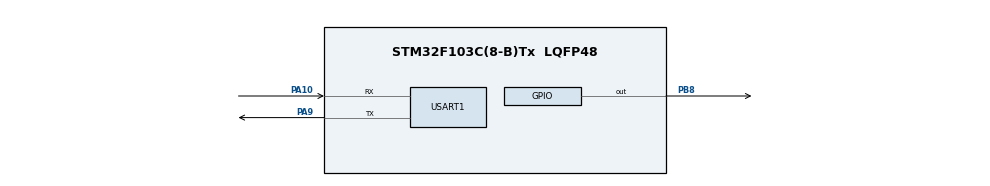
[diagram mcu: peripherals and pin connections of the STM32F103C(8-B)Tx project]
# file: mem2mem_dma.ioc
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Dma.MEMTOMEM.0.Direction=DMA_MEMORY_TO_MEMORY
Dma.MEMTOMEM.0.Instance=DMA1_Channel2
Dma.MEMTOMEM.0.MemDataAlignment=DMA_MDATAALIGN_BYTE
Dma.MEMTOMEM.0.MemInc=DMA_MINC_ENABLE
Dma.MEMTOMEM.0.Mode=DMA_NORMAL
Dma.MEMTOMEM.0.PeriphDataAlignment=DMA_PDATAALIGN_BYTE
Dma.MEMTOMEM.0.PeriphInc=DMA_PINC_ENABLE
Dma.MEMTOMEM.0.Priority=DMA_PRIORITY_LOW
Dma.Request0=MEMTOMEM
Mcu.Family=STM32F1
Mcu.Name=STM32F103C(8-B)Tx
Mcu.Package=LQFP48
NVIC.PriorityGroup=NVIC_PRIORITYGROUP_4
PA10.Mode=Asynchronous
PA10.Signal=USART1_RX
PA9.Mode=Asynchronous
PA9.Signal=USART1_TX
PB8.PinState=GPIO_PIN_SET
PB8.Signal=GPIO_Output
ProjectManager.HeapSize=0x200
ProjectManager.StackSize=0x400
ProjectManager.TargetToolchain=MDK-ARM V5.32
RCC.APB1Freq_Value=8000000
RCC.APB2Freq_Value=8000000
USART1.VirtualMode=VM_ASYNC
VP_SYS_VS_ND.Mode=No_Debug
board=custom

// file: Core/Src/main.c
/* USER CODE BEGIN Header */
/**
  ******************************************************************************
  * @file           : main.c
  * @brief          : Main program body
  ******************************************************************************
  * @attention
  *
  * Copyright (c) 2023 STMicroelectronics.
  * All rights reserved.
  *
  * This software is licensed under terms that can be found in the LICENSE file
  * in the root directory of this software component.
  * If no LICENSE file comes with this software, it is provided AS-IS.
  *
  ******************************************************************************
  */
/* USER CODE END Header */
#include "main.h"
#include "dma.h"
#include "usart.h"
#include "gpio.h"

/* USER CODE BEGIN Includes */
#include <stdio.h>
/* USER CODE END Includes */

/* USER CODE BEGIN PM */

#define BUF_SIZE 16

/* USER CODE END PM */

/* USER CODE BEGIN PV */

uint32_t srcBuf[BUF_SIZE] = {
0x00000000,0x11111111,0x22222222,0x33333333,
0x44444444,0x55555555,0x66666666,0x77777777,
0x88888888,0x99999999,0xAAAAAAAA,0xBBBBBBBB,
0xCCCCCCCC,0xDDDDDDDD,0xEEEEEEEE,0xFFFFFFFF
};
// Ŀ������
uint32_t desBuf[BUF_SIZE];

int fputc(int ch, FILE *f)
{
unsigned char temp[1]={ch};
HAL_UART_Transmit(&huart1,temp,1,0xffff);
return ch;
}

/* USER CODE END PV */

void SystemClock_Config(void);

int main(void)
{
  /* USER CODE BEGIN 1 */
	int i;
  /* USER CODE END 1 */

  /* MCU Configuration--------------------------------------------------------*/

  /* Reset of all peripherals, Initializes the Flash interface and the Systick. */
  HAL_Init();

  /* Configure the system clock */
  SystemClock_Config();

  /* Initialize all configured peripherals */
  MX_GPIO_Init();
  MX_DMA_Init();
  MX_USART1_UART_Init();
  /* USER CODE BEGIN 2 */

	HAL_DMA_Start(&hdma_memtomem_dma1_channel2,(uint32_t)srcBuf, (uint32_t)desBuf, sizeof(uint32_t) * BUF_SIZE);

	while(__HAL_DMA_GET_FLAG(&hdma_memtomem_dma1_channel2, DMA_FLAG_TC2) == RESET);
// ��ӡ��������
	for (i = 0; i < BUF_SIZE; i++)
		printf("Buf[%d] = %X\r\n", i, desBuf[i]);

  /* USER CODE END 2 */

  /* Infinite loop */
  while (1)
  {

  }
}

void SystemClock_Config(void)
{
  RCC_OscInitTypeDef RCC_OscInitStruct = {0};
  RCC_ClkInitTypeDef RCC_ClkInitStruct = {0};

  /** Initializes the RCC Oscillators according to the specified parameters
  * in the RCC_OscInitTypeDef structure.
  */
  RCC_OscInitStruct.OscillatorType = RCC_OSCILLATORTYPE_HSI;
  RCC_OscInitStruct.HSIState = RCC_HSI_ON;
  RCC_OscInitStruct.HSICalibrationValue = RCC_HSICALIBRATION_DEFAULT;
  RCC_OscInitStruct.PLL.PLLState = RCC_PLL_NONE;
  if (HAL_RCC_OscConfig(&RCC_OscInitStruct) != HAL_OK)
  {
    Error_Handler();
  }

  /** Initializes the CPU, AHB and APB buses clocks
  */
  RCC_ClkInitStruct.ClockType = RCC_CLOCKTYPE_HCLK|RCC_CLOCKTYPE_SYSCLK
                              |RCC_CLOCKTYPE_PCLK1|RCC_CLOCKTYPE_PCLK2;
  RCC_ClkInitStruct.SYSCLKSource = RCC_SYSCLKSOURCE_HSI;
  RCC_ClkInitStruct.AHBCLKDivider = RCC_SYSCLK_DIV1;
  RCC_ClkInitStruct.APB1CLKDivider = RCC_HCLK_DIV1;
  RCC_ClkInitStruct.APB2CLKDivider = RCC_HCLK_DIV1;

  if (HAL_RCC_ClockConfig(&RCC_ClkInitStruct, FLASH_LATENCY_0) != HAL_OK)
  {
    Error_Handler();
  }
}

void Error_Handler(void)
{
  __disable_irq();
  while (1)
  {
  }
}
